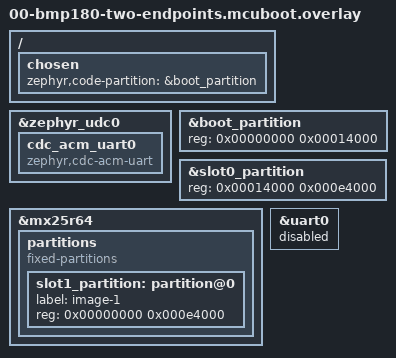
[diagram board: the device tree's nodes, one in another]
/*
 * SPDX-FileCopyrightText: 2026 The MCUHome Contributors
 * SPDX-License-Identifier: Apache-2.0
 *
 * Generated by mcuhome from 00-bmp180-two-endpoints.yaml — do not edit.
 *
 * Board: nrf7002dk/nrf5340/cpuapp.
 *
 * Devicetree for the MCUboot image. Sysbuild finds this file by name and hands it to the bootloader
 * image as its devicetree overlay.
 *
 * It REPLACES the overlay MCUboot would otherwise pick up rather than adding to it, which is why
 * the two upstream fragments it needs are restated below instead of referenced: the chosen entry
 * that links MCUboot into its own partition (MCUboot's boot/zephyr/app.overlay) and the CDC-ACM
 * function serial recovery talks over (its usb_cdc_acm.overlay).
 *
 * The flash layout below is byte-identical to the one in the application's board overlay. Both
 * images have to see the same flash map: the bootloader writes the slots, the application is linked
 * into one of them.
 */

/ {
	chosen {
		zephyr,code-partition = &boot_partition;
	};
};

&zephyr_udc0 {
	cdc_acm_uart0 {
		compatible = "zephyr,cdc-acm-uart";
	};
};

/* Flash layout (ADR 0015). MCUHome fixes the partition table itself rather than inheriting the
 * board's, because no upstream default holds an MCUHome image: the two-slot table this board ships
 * with gives the application 464 KiB, and a commissioned Matter node is over 550 KiB.
 * The storage partition keeps the address and size the board's own devicetree gives it. That is
 * what makes an update not a re-commissioning: the Matter fabric credentials and the Thread dataset
 * live there, and every layout in ADR 0015 preserves them.
 *
 *   mcuboot  internal 0x000000..0x014000    80 KiB
 *   image-0  internal 0x014000..0x0f8000   912 KiB
 *   storage  internal 0x0f8000..0x100000    32 KiB
 *   image-1  mx25r64  0x000000..0x0e4000   912 KiB
 */
/delete-node/ &slot1_partition;

&boot_partition {
	reg = <0x00000000 0x00014000>;
};

&slot0_partition {
	reg = <0x00014000 0x000e4000>;
};

&mx25r64 {
	status = "okay";

	partitions {
		compatible = "fixed-partitions";
		#address-cells = <1>;
		#size-cells = <1>;

		slot1_partition: partition@0 {
			label = "image-1";
			reg = <0x00000000 0x000e4000>;
		};
	};
};

/* Dead UART. MCUBOOT_SERIAL selects SERIAL and UART_INTERRUPT_DRIVEN unconditionally, regardless of
 * which serial-recovery transport is chosen — an upstream imprecision (workspace UPSTREAM-BUGS.md
 * entry M2). With BOOT_SERIAL_CDC_ACM as the transport here, that links in a UART driver the
 * bootloader never opens. Disabling the node it would bind to drops it: measured -1.30 KiB. */
&uart0 {
	status = "disabled";
};
